VERSION ""

NS_ :

BS_:

BU_: Amplifier VCU

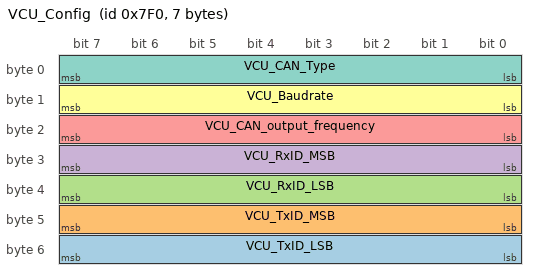
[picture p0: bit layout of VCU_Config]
BO_ 2032 VCU_Config: 7 VCU
 SG_ VCU_TxID_LSB : 55|8@0+ (1,0) [0|0] "" Vector__XXX
 SG_ VCU_TxID_MSB : 47|8@0+ (1,0) [0|0] "" Vector__XXX
 SG_ VCU_RxID_LSB : 39|8@0+ (1,0) [0|0] "" Vector__XXX
 SG_ VCU_RxID_MSB : 31|8@0+ (1,0) [0|0] "" Vector__XXX
 SG_ VCU_CAN_output_frequency : 23|8@0+ (1,0) [0|0] "" Vector__XXX
 SG_ VCU_Baudrate : 15|8@0+ (1,0) [0|0] "" Vector__XXX
 SG_ VCU_CAN_Type : 7|8@0+ (1,0) [0|0] "" Vector__XXX

BO_ 1008 XN4C_Output: 3 Amplifier
 SG_ XN4C_Ambient_Temp : 23|8@0- (1,0) [0|0] "C" Vector__XXX
 SG_ XN4C_outputVoltage : 7|16@0- (1,0) [-32768|32767] "mV" Vector__XXX
